# haltium_flpr register map
Vendor: Nordic Semiconductor; Series: nRFHaltium; File version: 1
Registers are 32-bit, read-write, reset 0x0 unless marked. A register's access mark holds for its fields unless they carry their own. Offsets are from the block's base; [hi:lo] are bit positions; lines under a group give offsets from that group; {n}, {i} and the like mark numbered series; 'fields as' and 'values as' point back to an identical list.

## GLOBAL_TDDCONF_S — TDDCONF
Base 0xBF001000
0x400 SYSPWRUPREQ — System power-up request
  [0] ACTIVE — Activate power-up request
    0=NotActive (Power-up request not active); 1=Active (Power-up request active)
0x404 DBGPWRUPREQ — Debug power-up request
  fields as SYSPWRUPREQ
0x408 TRACEPORTSPEED — Trace port trace clock speed
  [1:0] SPEED — Trace clock speed
    0=Speed25MHz; 1=Speed12500KHz (Speed 12.5MHz); 2=Speed6250KHz (Speed 6.25MHz); 3=Speed3125KHz (Speed 3.125MHz)
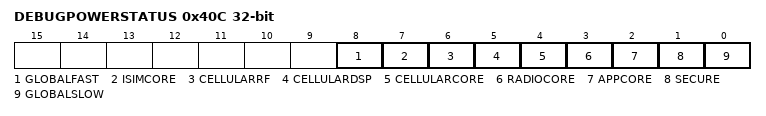
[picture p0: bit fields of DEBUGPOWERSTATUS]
0x40C DEBUGPOWERSTATUS — Debug mode power request status per major power domains
  [all] fields
    0=NotPowerReq (Power not requested); 1=Power requested
  [8] GLOBALFAST — Global fast peripherals domain
  [7] ISIMCORE — ISIM core domain
  [6] CELLULARRF — Cellular RF domain
  [5] CELLULARDSP — Cellular DSP domain
  [4] CELLULARCORE — Cellular core domain
  [3] RADIOCORE — Radio core domain
  [2] APPCORE — Application core domain
  [1] SECURE — Secure domain
  [0] GLOBALSLOW — Global slow peripherals domain

## GLOBAL_GGENERIC60_NS — GENERIC 0
Base 0xBF003000
Same registers: GLOBAL_GGENERIC60_S 0xBF003000 (alternate view of GLOBAL_GGENERIC60_NS), GLOBAL_TSGEN_NS 0xBF041000, GLOBAL_ETB_NS 0xBF044000, GLOBAL_ETR_NS 0xBF045000
0x00 TASKS_GENERICTASK wo — Generic event
  [0] TASKS_GENERICTASK
    1=Trigger task
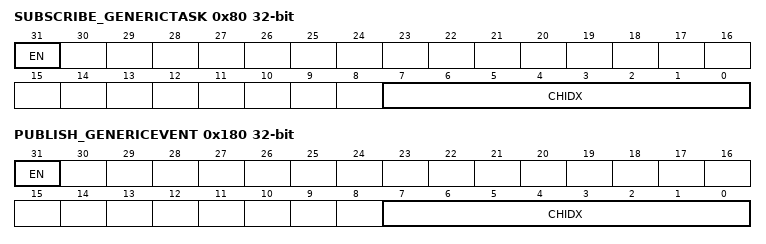
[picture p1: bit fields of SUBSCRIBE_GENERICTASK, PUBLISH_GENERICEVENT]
0x80 SUBSCRIBE_GENERICTASK — Subscribe configuration for task GENERICTASK
  [31] EN
    0=Disabled (Disable subscription); 1=Enabled (Enable subscription)
  [7:0] CHIDX — DPPI channel that task GENERICTASK will subscribe to
0x100 EVENTS_GENERICEVENT — Generic event
  [0] EVENTS_GENERICEVENT
    0=NotGenerated (Event not generated); 1=Generated (Event generated)
0x180 PUBLISH_GENERICEVENT — Publish configuration for event GENERICEVENT
  [31] EN
    0=Disabled (Disable publishing); 1=Enabled (Enable publishing)
  [7:0] CHIDX — DPPI channel that event GENERICEVENT will publish to
0x300 INTEN — Enable or disable interrupt
  [0] GENERICEVENT — Enable or disable interrupt for event GENERICEVENT
    0=Disabled; 1=Enabled
0x304 INTENSET — Enable interrupt
  [0] GENERICEVENT — Write '1' to enable interrupt for event GENERICEVENT
    on read: 0=Disabled (Read: Disabled); 1=Enabled (Read: Enabled) | on write: 1=Set (Enable)
0x308 INTENCLR — Disable interrupt
  [0] GENERICEVENT — Write '1' to disable interrupt for event GENERICEVENT
    on read: 0=Disabled (Read: Disabled); 1=Enabled (Read: Enabled) | on write: 1=Clear (Disable)

## GLOBAL_GIPCT0_NS — IPCT APB registers 0
Base 0x4F8D1000
Same registers: GLOBAL_GIPCT1_NS 0x4F921000, GLOBAL_GIPCT0_S 0x5F8D1000, GLOBAL_GIPCT1_S 0x5F921000
{0x0+4i} TASKS_SEND[{i}] (i=0..15) wo — Description collection: Send [n] task
  [0] TASKS_SEND — Send [n] task
    1=Trigger task
{0x40+4i} TASKS_ACK[{i}] (i=0..15) wo — Description collection: Acknowledge the RECEIVE[n] event
  [0] TASKS_ACK — Acknowledge the RECEIVE[n] event
    1=Trigger task
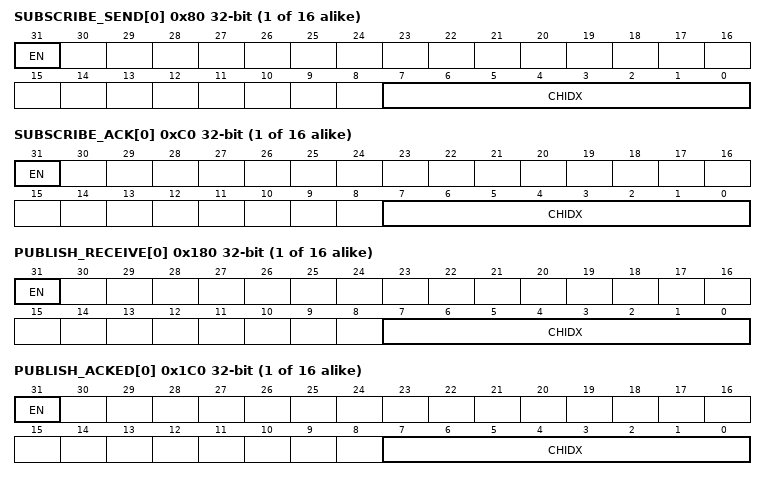
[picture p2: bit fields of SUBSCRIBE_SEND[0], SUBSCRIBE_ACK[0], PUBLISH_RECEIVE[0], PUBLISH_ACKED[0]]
{0x80+4i} SUBSCRIBE_SEND[{i}] (i=0..15) — Description collection: Subscribe configuration for task SEND[n]
  [31] EN
    0=Disabled (Disable subscription); 1=Enabled (Enable subscription)
  [7:0] CHIDX — DPPI channel that task SEND[n] will subscribe to
{0xC0+4i} SUBSCRIBE_ACK[{i}] (i=0..15) — Description collection: Subscribe configuration for task ACK[n]
  [31] EN
    values as SUBSCRIBE_SEND[0].EN
  [7:0] CHIDX — DPPI channel that task ACK[n] will subscribe to
{0x100+4i} EVENTS_RECEIVE[{i}] (i=0..15) — Description collection: Receive [n] event
  [0] EVENTS_RECEIVE — Receive [n] event
    0=NotGenerated (Event not generated); 1=Generated (Event generated)
{0x140+4i} EVENTS_ACKED[{i}] (i=0..15) — Description collection: Acknowledged event for the SEND[n] task
  [0] EVENTS_ACKED — Acknowledged event for the SEND[n] task
    values as EVENTS_RECEIVE[0].EVENTS_RECEIVE
{0x180+4i} PUBLISH_RECEIVE[{i}] (i=0..15) — Description collection: Publish configuration for event RECEIVE[n]
  [31] EN
    0=Disabled (Disable publishing); 1=Enabled (Enable publishing)
  [7:0] CHIDX — DPPI channel that event RECEIVE[n] will publish to
{0x1C0+4i} PUBLISH_ACKED[{i}] (i=0..15) — Description collection: Publish configuration for event ACKED[n]
  [31] EN
    values as PUBLISH_RECEIVE[0].EN
  [7:0] CHIDX — DPPI channel that event ACKED[n] will publish to
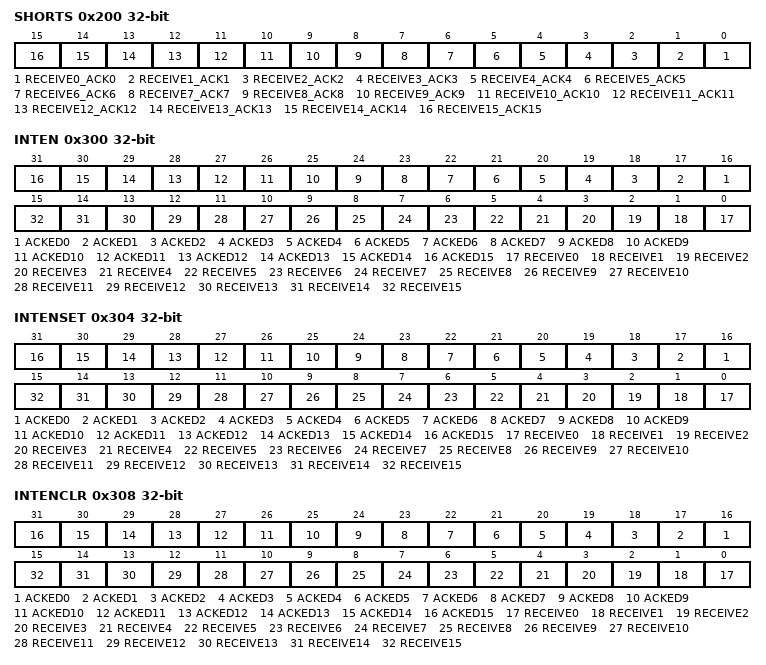
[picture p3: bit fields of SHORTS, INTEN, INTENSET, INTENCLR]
0x200 SHORTS — Shortcuts between local events and tasks
  [all] fields
    0=Disabled (Disable shortcut); 1=Enabled (Enable shortcut)
  [n] RECEIVE{n}_ACK{n} (n=0..15) — Shortcut between event RECEIVE[{n}] and task ACK[{n}]
0x300 INTEN — Enable or disable interrupt
  [all] fields
    0=Disabled; 1=Enabled
  [n+16] ACKED{n} (n=0..15) — Enable or disable interrupt for event ACKED[{n}]
  [n] RECEIVE{n} (n=0..15) — Enable or disable interrupt for event RECEIVE[{n}]
0x304 INTENSET — Enable interrupt
  [all] fields
    on read: 0=Disabled (Read: Disabled); 1=Enabled (Read: Enabled) | on write: 1=Set (Enable)
  [n+16] ACKED{n} (n=0..15) — Write '1' to enable interrupt for event ACKED[{n}]
  [n] RECEIVE{n} (n=0..15) — Write '1' to enable interrupt for event RECEIVE[{n}]
0x308 INTENCLR — Disable interrupt
  [all] fields
    on read: 0=Disabled (Read: Disabled); 1=Enabled (Read: Enabled) | on write: 1=Clear (Disable)
  [n+16] ACKED{n} (n=0..15) — Write '1' to disable interrupt for event ACKED[{n}]
  [n] RECEIVE{n} (n=0..15) — Write '1' to disable interrupt for event RECEIVE[{n}]
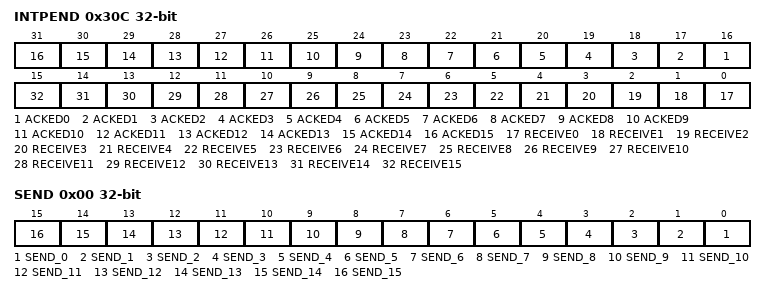
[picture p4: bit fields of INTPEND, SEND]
0x30C INTPEND ro — Pending interrupts
  [all] fields
    on read: 0=NotPending (Read: Not pending); 1=Pending (Read: Pending)
  [n+16] ACKED{n} (n=0..15) — Read pending status of interrupt for event ACKED[{n}]
  [n] RECEIVE{n} (n=0..15) — Read pending status of interrupt for event RECEIVE[{n}]
0x400 OVERFLOW group — Unspecified
  0x00 SEND — The task overflow status for SEND tasks Write 0 to clear
    [all] fields
      1=Overflow (Task overflow is happened); 0=NoOverflow (Task overflow is not happened)
    [n] SEND_{n} (n=0..15) — The status for SEND [{n}] task overflow
